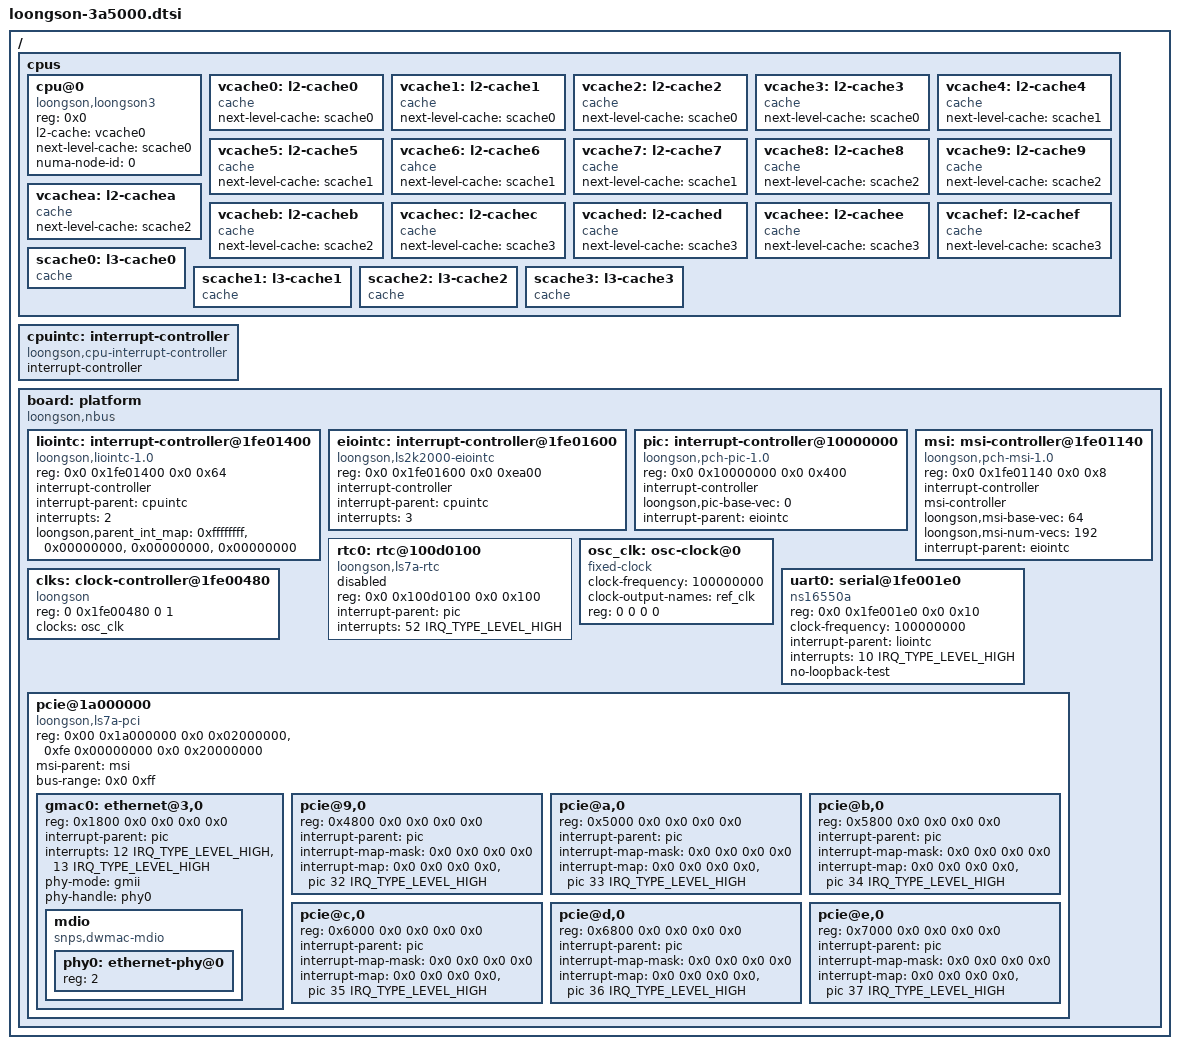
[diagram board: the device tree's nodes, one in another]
// SPDX-License-Identifier: GPL-2.0
/*
* Copyright (C) 2023 Loongson Technology Corporation Limited
*/

/dts-v1/;

#include <dt-bindings/interrupt-controller/irq.h>

/ {
	cpus {
		#address-cells = <1>;
		#size-cells = <0>;
		
		cpu@0 {
			compatible = "loongson,loongson3";
			device_type = "cpu";
			reg = <0x0>;
			l2-cache = <&vcache0>;
			next-level-cache = <&scache0>;
			numa-node-id = <0>;
		};
		vcache0: l2-cache0 {
			compatible = "cache";
			next-level-cache = <&scache0>;
		};
		vcache1: l2-cache1 {
			compatible = "cache";
			next-level-cache = <&scache0>;
		};
		vcache2: l2-cache2 {
			compatible = "cache";
			next-level-cache = <&scache0>;
		};
		vcache3: l2-cache3 {
			compatible = "cache";
			next-level-cache = <&scache0>;
		};
		vcache4: l2-cache4 {
			compatible = "cache";
			next-level-cache = <&scache1>;
		};
		vcache5: l2-cache5 {
			compatible = "cache";
			next-level-cache = <&scache1>;
		};
		vcache6: l2-cache6 {
			compatible = "cahce";
			next-level-cache = <&scache1>;
		};
		vcache7: l2-cache7 {
			compatible = "cache";
			next-level-cache = <&scache1>;
		};
		vcache8: l2-cache8 {
			compatible = "cache";
			next-level-cache = <&scache2>;
		};
		vcache9: l2-cache9 {
			compatible = "cache";
			next-level-cache = <&scache2>;
		};
		vcachea: l2-cachea {
			compatible = "cache";
			next-level-cache = <&scache2>;
		};
		vcacheb: l2-cacheb {
			compatible = "cache";
			next-level-cache = <&scache2>;
		};
		vcachec: l2-cachec {
			compatible = "cache";
			next-level-cache = <&scache3>;
		};
		vcached: l2-cached {
			compatible = "cache";
			next-level-cache = <&scache3>;
		};
		vcachee: l2-cachee {
			compatible = "cache";
			next-level-cache = <&scache3>;
		};
		vcachef: l2-cachef {
			compatible = "cache";
			next-level-cache = <&scache3>;
		};
		scache0: l3-cache0 {
			compatible = "cache";
		};
		scache1: l3-cache1 {
			compatible = "cache";
		};
		scache2: l3-cache2 {
			compatible = "cache";
		};
		scache3: l3-cache3 {
			compatible = "cache";
	}; };
};

/ {
	#address-cells = <2>;
	#size-cells = <2>;
	
	cpuintc: interrupt-controller {
		compatible = "loongson,cpu-interrupt-controller";
		#interrupt-cells = <1>;// 中断标识符用一个 cell (32b)
		interrupt-controller;
		phandle = <0x8001>;// node 引用号
	};
	
	board: platform {
		compatible = "loongson,nbus", "simple-bus";
		// simple-bus，子设备的 reg 区域和物理地址一一对应
		
		// ranges 地址映射，bus 地址空间映射到 CPU 地址空间
		// 由于 addr 和 size cell 均为 2，所以每 8 bytes 一组（前高位，后低位）
		// 【子设备地址】【父设备地址】【大小】
		ranges = <
		0x00  0x10000000  0x00  0x10000000  0x00  0x10000000
		0x00  0x02000000  0x00  0x02000000  0x00  0x02000000
		0x00  0x20000000  0x00  0x20000000  0x00  0x10000000
		0x00  0x40000000  0x00  0x40000000  0x00  0x40000000
		0xfe  0x00000000  0xfe  0x00000000  0x00  0x40000000
		>;
		
		#address-cells = <2>;
		#size-cells = <2>;
		
		liointc: interrupt-controller@1fe01400 {
			compatible = "loongson,liointc-1.0";
			reg = <0x0 0x1fe01400 0x0 0x64>;
			interrupt-controller;
			#interrupt-cells = <2>;// 【IRQ number】【IRQ trigger】
			interrupt-parent = <&cpuintc>;
			interrupts = <2>;// 作为 cpuintc 的 HWI 2
			interrupt-names = "int0";
			loongson,parent_int_map =
			<0xffffffff>, /* int0 */// 32 个 liointc 中断路由给 CPU 的 int0 中断线
			<0x00000000>, /* int1 */
			<0x00000000>, /* int2 */
			<0x00000000>; /* int3 */
		};
		
		eiointc: interrupt-controller@1fe01600 {
			compatible = "loongson,ls2k2000-eiointc";// 没找到 3 系的 eiointc 驱动，估计复用了 2K 系列的
			reg = <0x0 0x1fe01600 0x0 0xea00>;
			interrupt-controller;
			#interrupt-cells = <1>;
			interrupt-parent = <&cpuintc>;
			interrupts = <3>;// cpuintc 的 HWI 3
			phandle = <0x8002>;
		};
		
		pic: interrupt-controller@10000000 {
			compatible = "loongson,pch-pic-1.0";// Platform Controller Hub - Programmable Interrupt Controller
			reg = <0x0 0x10000000 0x0 0x400>;
			interrupt-controller;
			#interrupt-cells = <2>;
			loongson,pic-base-vec = <0>;// PIC 起始中断向量号
			interrupt-parent = <&eiointc>;// eiointc-pic
			phandle = <0x8003>;
		};
		
		msi: msi-controller@1fe01140 {
			compatible = "loongson,pch-msi-1.0";
			reg = <0x0 0x1fe01140 0x0 0x8>;
			interrupt-controller;
			#interrupt-cells = <1>;
			msi-controller;// msi 控制器
			loongson,msi-base-vec = <64>;// MSI 起始中断向量号
			loongson,msi-num-vecs = <192>;// MSI 最大向量数
			interrupt-parent = <&eiointc>;// eiointc-msi
			phandle = <0x8004>;
		};
		
		rtc0: rtc@100d0100 {
			compatible = "loongson,ls7a-rtc";// Real Time Clock
			reg = <0x0 0x100d0100 0x0 0x100>;
			interrupt-parent = <&pic>;// pic-rtc0
			interrupts = <52 IRQ_TYPE_LEVEL_HIGH>;
			status = "disabled";
		};
		
		osc_clk: osc-clock@0 {
			#clock-cells = <0>;
			compatible = "fixed-clock";
			clock-frequency = <100000000>;
			clock-output-names = "ref_clk";
			reg = <0 0 0 0>;
		};
		
		clks: clock-controller@1fe00480 {
			compatible = "loongson";
			reg = <0 0x1fe00480 0 1>;
			clocks = <&osc_clk>;// clks-osc_clk
			clock-names = "ref_clk";
			#clock-cells = <1>;
		};
		
		uart0: serial@1fe001e0 {
			compatible = "ns16550a";
			reg = <0x0 0x1fe001e0 0x0 0x10>;
			clock-frequency = <100000000>;// 100M
			interrupt-parent = <&liointc>;
			interrupts = <10 IRQ_TYPE_LEVEL_HIGH>;// liointc IRQ 10
			no-loopback-test;
			// status = "disabled";
		};
		
		
		pcie@1a000000 {
			compatible = "loongson,ls7a-pci";
			reg =
			<0x00 0x1a000000 0x0 0x02000000>,// PCIe 配置空间
			<0xfe 0x00000000 0x0 0x20000000>;// HT保留地址空间（PCI配置访问地址）
			#address-cells = <3>;
			#size-cells = <2>;
			device_type = "pci";
			msi-parent = <&msi>;// MSI 由 msi 节点负责
			bus-range = <0x0 0xff>;// bus 号的范围
			// PCIe 空间映射
			ranges =
			<0x01000000 0x0 0x00008000 0x0 0x18408000 0x0 0x00008000>,// 0x01000000（IO）【PCIe空间基地址】【CPU空间地址】【大小】
			<0x02000000 0x0 0x60000000 0x0 0x60000000 0x0 0x20000000>;// 0x02000000（MEM）【PCIe空间基地址】【CPU空间地址】【大小】
			
			gmac0: ethernet@3,0 {
				reg = <0x1800 0x0 0x0 0x0 0x0>;
				interrupt-parent = <&pic>;
				interrupts = <12 IRQ_TYPE_LEVEL_HIGH>,
				<13 IRQ_TYPE_LEVEL_HIGH>;
				interrupt-names = "macirq", "eth_lpi";
				
				phy-mode = "gmii";
				phy-handle = <&phy0>;
				mdio {
					compatible = "snps,dwmac-mdio";
					#address-cells = <1>;
					#size-cells = <0>;
					phy0: ethernet-phy@0 {
						reg = <2>;
					};
				};
				// status = "disabled";
			};
			
			pcie@9,0 {
				reg = <0x4800 0x0 0x0 0x0 0x0>;
				#address-cells = <3>;
				#size-cells = <2>;
				device_type = "pci";
				interrupt-parent = <&pic>;
				#interrupt-cells = <1>;
				interrupt-map-mask = <0x0 0x0 0x0 0x0>;
				interrupt-map = <0x0 0x0 0x0 0x0 &pic 32 IRQ_TYPE_LEVEL_HIGH>;
				ranges;
			};// f0p0
			
			pcie@a,0 {
				reg = <0x5000 0x0 0x0 0x0 0x0>;
				#address-cells = <3>;
				#size-cells = <2>;
				device_type = "pci";
				interrupt-parent = <&pic>;
				#interrupt-cells = <1>;
				interrupt-map-mask = <0x0 0x0 0x0 0x0>;
				interrupt-map = <0x0 0x0 0x0 0x0 &pic 33 IRQ_TYPE_LEVEL_HIGH>;
				ranges;
			};// f0p1
			
			pcie@b,0 {
				reg = <0x5800 0x0 0x0 0x0 0x0>;
				#address-cells = <3>;
				#size-cells = <2>;
				device_type = "pci";
				interrupt-parent = <&pic>;
				#interrupt-cells = <1>;
				interrupt-map-mask = <0x0 0x0 0x0 0x0>;
				interrupt-map = <0x0 0x0 0x0 0x0 &pic 34 IRQ_TYPE_LEVEL_HIGH>;
				ranges;
			};// f0p2
			
			pcie@c,0 {
				reg = <0x6000 0x0 0x0 0x0 0x0>;
				#address-cells = <3>;
				#size-cells = <2>;
				device_type = "pci";
				interrupt-parent = <&pic>;
				#interrupt-cells = <1>;
				interrupt-map-mask = <0x0 0x0 0x0 0x0>;
				interrupt-map = <0x0 0x0 0x0 0x0 &pic 35 IRQ_TYPE_LEVEL_HIGH>;
				ranges;
			};// f0p3
			
			pcie@d,0 {
				reg = <0x6800 0x0 0x0 0x0 0x0>;
				#address-cells = <3>;
				#size-cells = <2>;
				device_type = "pci";
				interrupt-parent = <&pic>;
				#interrupt-cells = <1>;
				interrupt-map-mask = <0x0 0x0 0x0 0x0>;
				interrupt-map = <0x0 0x0 0x0 0x0 &pic 36 IRQ_TYPE_LEVEL_HIGH>;
				ranges;
			};// f1p0
			
			pcie@e,0 {
				reg = <0x7000 0x0 0x0 0x0 0x0>;
				#address-cells = <3>;
				#size-cells = <2>;
				device_type = "pci";
				interrupt-parent = <&pic>;
				#interrupt-cells = <1>;
				interrupt-map-mask = <0x0 0x0 0x0 0x0>;
				interrupt-map = <0x0 0x0 0x0 0x0 &pic 37 IRQ_TYPE_LEVEL_HIGH>;
				ranges;
			};// f1p1
			
		};
	};
	
};
